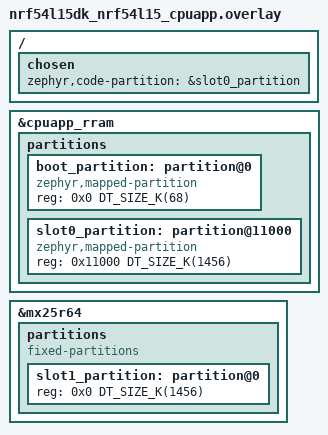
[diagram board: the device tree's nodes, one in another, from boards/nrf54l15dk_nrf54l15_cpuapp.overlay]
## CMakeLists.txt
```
#
# Copyright (c) 2021 Nordic Semiconductor ASA
#
# SPDX-License-Identifier: LicenseRef-Nordic-5-Clause
#

cmake_minimum_required(VERSION 3.13.1)

find_package(Zephyr REQUIRED HINTS $ENV{ZEPHYR_BASE})
project(NONE)

FILE(GLOB app_sources src/*.c)
target_sources(app PRIVATE ${app_sources})
target_include_directories(app PRIVATE .)
```

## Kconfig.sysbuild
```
#
# Copyright (c) 2024 Nordic Semiconductor
#
# SPDX-License-Identifier: LicenseRef-Nordic-5-Clause
#

choice MCUBOOT_MODE
	default MCUBOOT_MODE_OVERWRITE_ONLY if SOC_SERIES_NRF53
endchoice

choice NETCORE
	default NETCORE_EMPTY if SOC_NRF5340_CPUAPP
endchoice

config SECURE_BOOT_NETCORE
	default y if SOC_NRF5340_CPUAPP

config NETCORE_APP_UPDATE
	default y if SOC_NRF5340_CPUAPP

source "share/sysbuild/Kconfig"
```

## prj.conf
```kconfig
#
# Copyright (c) 2021-2023 Nordic Semiconductor ASA
#
# SPDX-License-Identifier: LicenseRef-Nordic-5-Clause
#

CONFIG_ZTEST=y

CONFIG_BOOTLOADER_MCUBOOT=y
```

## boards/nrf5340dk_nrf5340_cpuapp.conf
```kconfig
#
# Copyright (c) 2021 Nordic Semiconductor ASA
#
# SPDX-License-Identifier: LicenseRef-Nordic-5-Clause
#

CONFIG_SOC_NRF53_CPUNET_ENABLE=y
```

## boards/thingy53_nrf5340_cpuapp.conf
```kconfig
#
# Copyright (c) 2021 Nordic Semiconductor ASA
#
# SPDX-License-Identifier: LicenseRef-Nordic-5-Clause
#

CONFIG_BOARD_ENABLE_CPUNET=y
```

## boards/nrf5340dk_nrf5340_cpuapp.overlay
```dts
/delete-node/ &boot_partition;
/delete-node/ &slot0_partition;
/delete-node/ &slot1_partition;
/delete-node/ &storage_partition;

&flash0 {
	partitions {
		boot_partition: partition@0 {
			compatible = "zephyr,mapped-partition";
			label = "mcuboot";
			reg = <0x0 0xc000>;
		};

		slot0_partition: partition@c000 {
			compatible = "zephyr,mapped-partition";
			label = "image-0";
			reg = <0xc000 0xf4000>;
		};
	};
};

&mx25r64 {
	partitions {
		compatible = "fixed-partitions";
		#address-cells = <1>;
		#size-cells = <1>;

		slot1_partition: partition@0 {
			label = "image-1";
			reg = <0x0 0xf4000>;
		};

		slot3_partition: partition@f4000 {
			label = "image-3";
			reg = <0xf4000 0x40000>;
		};
	};
};
```

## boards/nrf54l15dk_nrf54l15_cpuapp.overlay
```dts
/*
 * Copyright (c) 2026 Nordic Semiconductor ASA
 *
 * SPDX-License-Identifier: LicenseRef-Nordic-5-Clause
 */

&cpuapp_rram {
	/delete-node/ partitions;

	partitions {
		ranges;
		#address-cells = <1>;
		#size-cells = <1>;

		boot_partition: partition@0 {
			compatible = "zephyr,mapped-partition";
			reg = <0x0 DT_SIZE_K(68)>;
		};

		slot0_partition: partition@11000 {
			compatible = "zephyr,mapped-partition";
			reg = <0x11000 DT_SIZE_K(1456)>;
		};
	};
};

&mx25r64 {
	status = "okay";

	partitions {
		compatible = "fixed-partitions";
		#address-cells = <1>;
		#size-cells = <1>;

		slot1_partition: partition@0 {
			reg = <0x0 DT_SIZE_K(1456)>;
		};
	};
};

/ {
	chosen {
		zephyr,code-partition = &slot0_partition;
	};
};
```

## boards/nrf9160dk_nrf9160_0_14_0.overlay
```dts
/* Copyright (c) 2021 Nordic Semiconductor ASA
 *
 * SPDX-License-Identifier: LicenseRef-Nordic-5-Clause
 */

/ {
	chosen {
		nordic,pm-ext-flash = &mx25r64;
	};
};
```

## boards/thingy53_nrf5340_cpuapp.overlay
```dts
/delete-node/ &boot_partition;
/delete-node/ &slot0_partition;
/delete-node/ &storage_partition;

&flash0 {
	partitions {
		boot_partition: partition@0 {
			compatible = "zephyr,mapped-partition";
			label = "mcuboot";
			reg = <0x0 0x20000>;
		};

		slot0_partition: partition@20000 {
			compatible = "zephyr,mapped-partition";
			label = "image-0";
			reg = <0x20000 0xe0000>;
		};
	};
};
```

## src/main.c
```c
/*
 * Copyright (c) 2021 Nordic Semiconductor ASA
 *
 * SPDX-License-Identifier: LicenseRef-Nordic-5-Clause
 */

#include <zephyr/ztest.h>
#include <stdio.h>


ZTEST(mcuboot_external_flash, test_external_flash)
{
	zassert_true(true, "Needed to pass.");
}

ZTEST_SUITE(mcuboot_external_flash, NULL, NULL, NULL, NULL, NULL);
```
